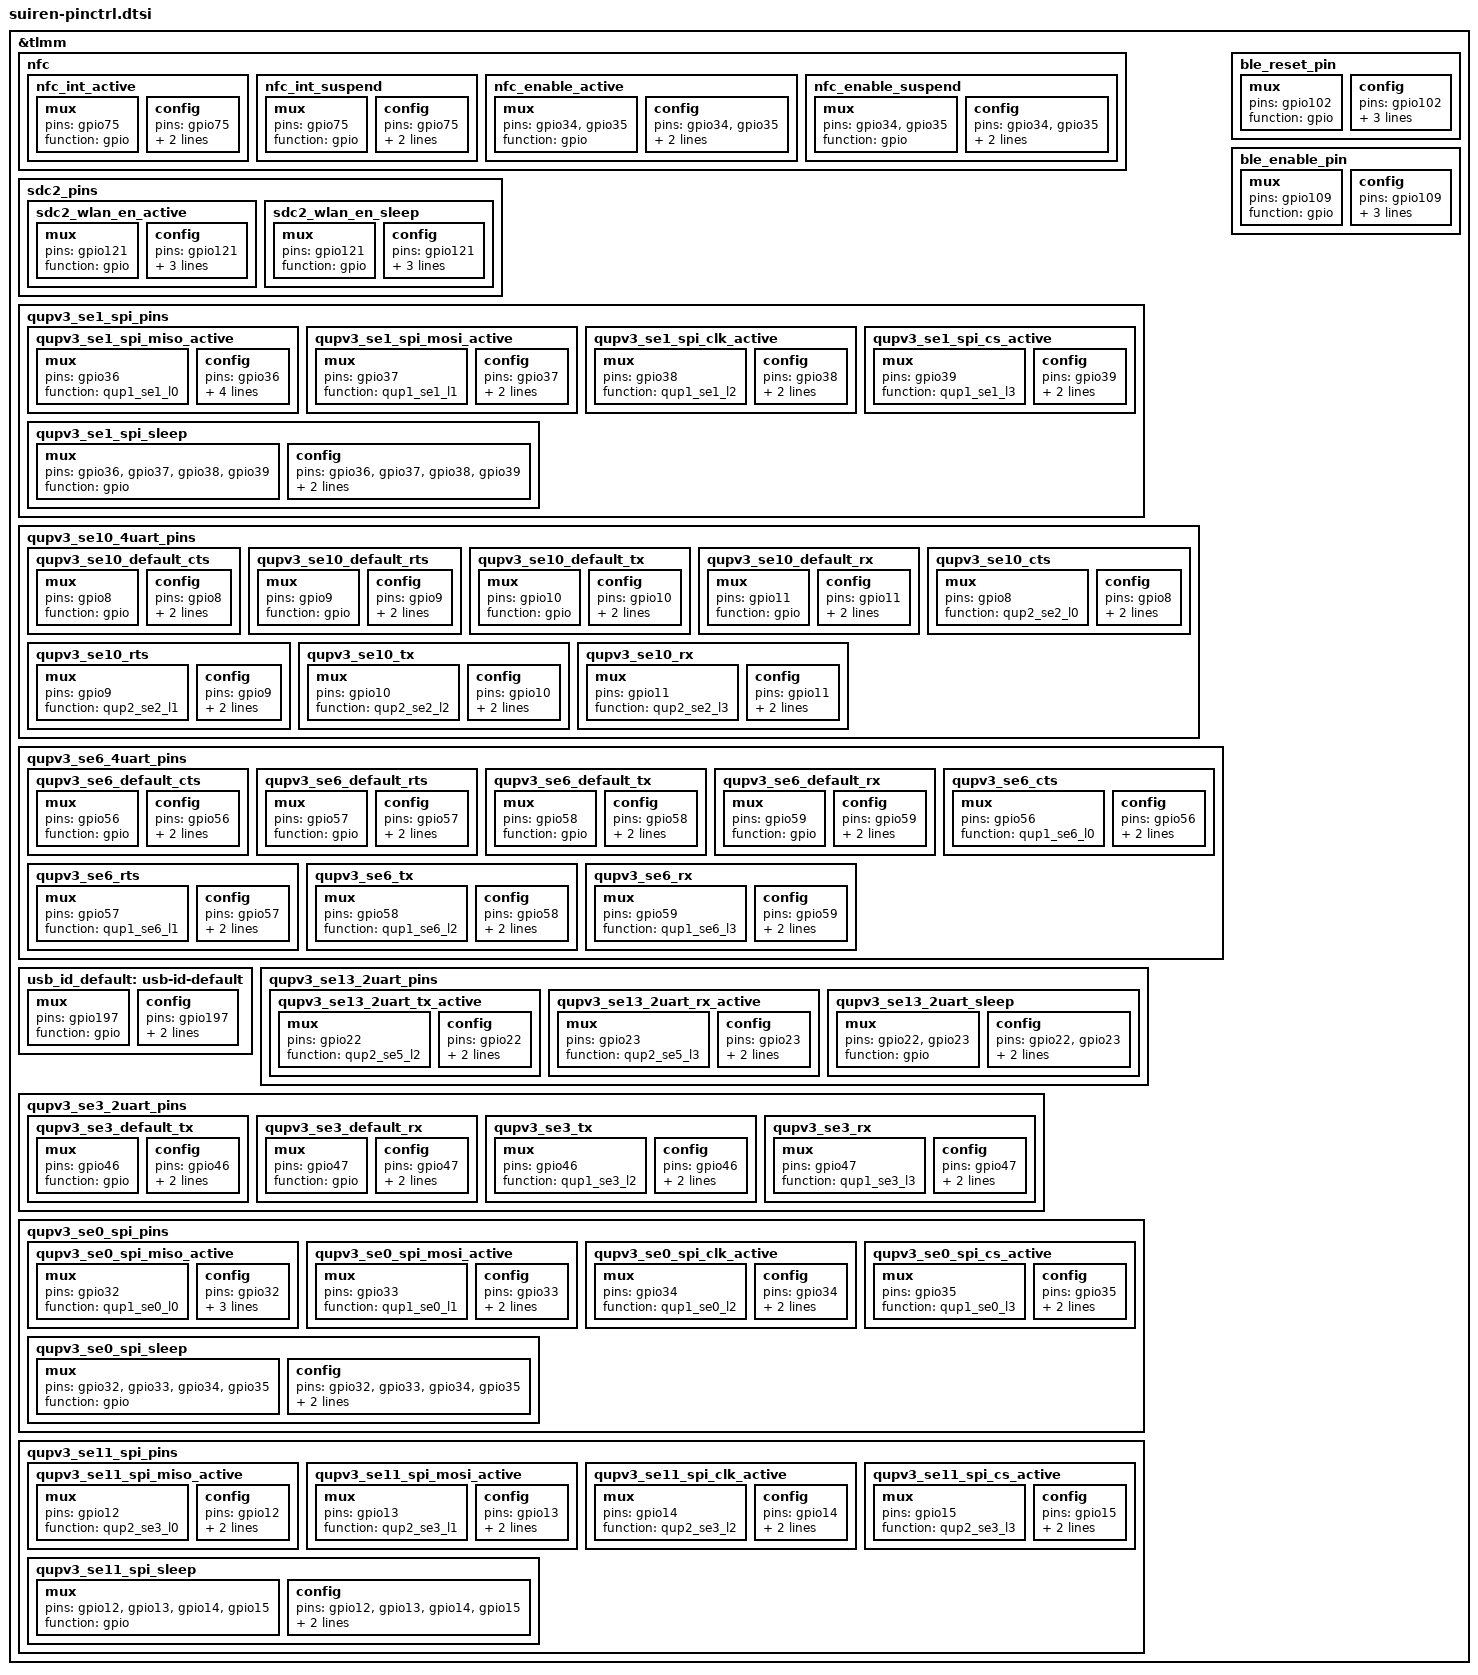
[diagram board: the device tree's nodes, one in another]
/*for suiren pinctrl */
&tlmm {
	nfc {
		nfc_int_active: nfc_int_active {
			/* active state */
			mux {
				/* NFC Read Interrupt */
				pins = "gpio75";
				function = "gpio";
			};

			config {
				pins = "gpio75";
				drive-strength = <2>; /* 2 MA */
				bias-pull-down;
			};
		};

		nfc_int_suspend: nfc_int_suspend {
			/* sleep state */
			mux {
				/* NFC Read Interrupt */
				pins = "gpio75";
				function = "gpio";
			};

			config {
				pins = "gpio75";
				drive-strength = <2>; /* 2 MA */
				bias-pull-down;
			};
		};

		nfc_enable_active: nfc_enable_active {
			mux {
				/* Enable, and Clock request gpios */
				pins = "gpio34", "gpio35";
				function = "gpio";
			};

			config {
				pins = "gpio34", "gpio35";
				drive-strength = <2>; /* 2 MA */
				bias-disable;
			};
		};

		nfc_enable_suspend: nfc_enable_suspend {
			mux {
				pins = "gpio34", "gpio35";
				function = "gpio";
			};

			config {
				pins = "gpio34", "gpio35";
				drive-strength = <2>; /* 2 MA */
				bias-disable;
			};
		};
	}; //nfc

	sdc2_pins {
		sdc2_wlan_en_active: sdc2_wlan_en_active {
			mux {
				pins = "gpio121";
				function = "gpio";
			};
			config {
				pins = "gpio121";
				drive-strength = <16>;
				output-high;
				bias-pull-up;
			};
		};
		sdc2_wlan_en_sleep: sdc2_wlan_en_sleep {
			mux {
				pins = "gpio121";
				function = "gpio";
			};
			config {
				pins = "gpio121";
				drive-strength = <2>;
				output-low;
				bias-pull-down;
			};
		};
	}; //wlan

	qupv3_se1_spi_pins: qupv3_se1_spi_pins {
		qupv3_se1_spi_miso_active: qupv3_se1_spi_miso_active {
			mux {
				pins = "gpio36";
				function = "qup1_se1_l0";
			};
			config {
				pins = "gpio36";
				drive-strength = <6>;
				bias-disable;
				bias-no-pull;
				input-enable;
			};
		};
		qupv3_se1_spi_mosi_active: qupv3_se1_spi_mosi_active {
			mux {
				pins = "gpio37";
				function = "qup1_se1_l1";
			};
			config {
				pins = "gpio37";
				drive-strength = <6>;
				bias-disable;
			};
		};
		qupv3_se1_spi_clk_active: qupv3_se1_spi_clk_active {
			mux {
				pins = "gpio38";
				function = "qup1_se1_l2";
			};
			config {
				pins = "gpio38";
				drive-strength = <6>;
				bias-disable;
			};
		};
		qupv3_se1_spi_cs_active: qupv3_se1_spi_cs_active {
			mux {
				pins = "gpio39";
				function = "qup1_se1_l3";
			};
			config {
				pins = "gpio39";
				drive-strength = <6>;
				bias-disable;
			};
		};
		qupv3_se1_spi_sleep: qupv3_se1_spi_sleep {
			mux {
				pins = "gpio36", "gpio37",
					"gpio38", "gpio39";
				function = "gpio";
			};
			config {
				pins = "gpio36", "gpio37",
					"gpio38", "gpio39";
				drive-strength = <6>;
				bias-disable;
			};
		};
	};

	/* bluetooth1 */
	qupv3_se10_4uart_pins: qupv3_se10_4uart_pins {
		qupv3_se10_default_cts: qupv3_se10_default_cts {
			mux {
				pins = "gpio8";
				function = "gpio";
			};
			config {
				pins = "gpio8";
				drive-strength = <2>;
				bias-disable;
			};
		};
		qupv3_se10_default_rts: qupv3_se10_default_rts {
			mux {
				pins = "gpio9";
				function = "gpio";
			};
			config {
				pins = "gpio9";
				drive-strength = <2>;
				bias-pull-down;
			};
		};
		qupv3_se10_default_tx: qupv3_se10_default_tx {
			mux {
				pins = "gpio10";
				function = "gpio";
			};
			config {
				pins = "gpio10";
				drive-strength = <2>;
				bias-pull-up;
			};
		};
		qupv3_se10_default_rx: qupv3_se10_default_rx {
			mux {
				pins = "gpio11";
				function = "gpio";
			};
			config {
				pins = "gpio11";
				drive-strength = <2>;
				bias-pull-down;
			};
		};
		qupv3_se10_cts: qupv3_se10_cts {
			mux {
				pins = "gpio8";
				function = "qup2_se2_l0";
			};
			config {
				pins = "gpio8";
				drive-strength = <2>;
				bias-disable;
			};
		};
		qupv3_se10_rts: qupv3_se10_rts {
			mux {
				pins = "gpio9";
				function = "qup2_se2_l1";
			};
			config {
				pins = "gpio9";
				drive-strength = <2>;
				bias-pull-down;
			};
		};
		qupv3_se10_tx: qupv3_se10_tx {
			mux {
				pins = "gpio10";
				function = "qup2_se2_l2";
			};
			config {
				pins = "gpio10";
				drive-strength = <2>;
				bias-pull-up;
			};
		};
		qupv3_se10_rx: qupv3_se10_rx {
			mux {
				pins = "gpio11";
				function = "qup2_se2_l3";
			};
			config {
				pins = "gpio11";
				drive-strength = <2>;
				bias-disable;
			};
		};
	}; // bluetooth1

	/* bluetooth le controller */
	qupv3_se6_4uart_pins: qupv3_se6_4uart_pins {
		qupv3_se6_default_cts: qupv3_se6_default_cts {
			mux {
				pins = "gpio56";
				function = "gpio";
			};
			config {
				pins = "gpio56";
				drive-strength = <2>;
				bias-disable;
			};
		};
		qupv3_se6_default_rts: qupv3_se6_default_rts {
			mux {
				pins = "gpio57";
				function = "gpio";
			};
			config {
				pins = "gpio57";
				drive-strength = <2>;
				bias-pull-down;
			};
		};
		qupv3_se6_default_tx: qupv3_se6_default_tx {
			mux {
				pins = "gpio58";
				function = "gpio";
			};
			config {
				pins = "gpio58";
				drive-strength = <2>;
				bias-pull-up;
			};
		};
		qupv3_se6_default_rx: qupv3_se6_default_rx {
			mux {
				pins = "gpio59";
				function = "gpio";
			};
			config {
				pins = "gpio59";
				drive-strength = <2>;
				bias-pull-down;
			};
		};
		qupv3_se6_cts: qupv3_se6_cts {
			mux {
				pins = "gpio56";
				function = "qup1_se6_l0";
			};
			config {
				pins = "gpio56";
				drive-strength = <2>;
				bias-disable;
			};
		};
		qupv3_se6_rts: qupv3_se6_rts {
			mux {
				pins = "gpio57";
				function = "qup1_se6_l1";
			};
			config {
				pins = "gpio57";
				drive-strength = <2>;
				bias-pull-down;
			};
		};
		qupv3_se6_tx: qupv3_se6_tx {
			mux {
				pins = "gpio58";
				function = "qup1_se6_l2";
			};
			config {
				pins = "gpio58";
				drive-strength = <2>;
				bias-pull-up;
			};
		};
		qupv3_se6_rx: qupv3_se6_rx {
			mux {
				pins = "gpio59";
				function = "qup1_se6_l3";
			};
			config {
				pins = "gpio59";
				drive-strength = <2>;
				bias-disable;
			};
		};
	};
	ble_reset_pin: ble_reset_pin {
		mux {
			pins = "gpio102";
			function = "gpio";
			};
		config {
			pins = "gpio102";
			drive-strength = <2>;
			output-low;
			bias-pull-down;
			};
	};
	ble_enable_pin: ble_enable_pin {
		mux {
			pins = "gpio109";
			function = "gpio";
			};
		config {
			pins = "gpio109";
			drive-strength = <2>;
			output-low;
			bias-pull-down;
			};
	};

	usb_id_default: usb-id-default {
		mux {
			pins = "gpio197";
			function = "gpio";
		};

		config {
			pins = "gpio197";
			drive-strength = <2>;
			bias-pull-up;
		};
	};

	qupv3_se13_2uart_pins: qupv3_se13_2uart_pins {
		qupv3_se13_2uart_tx_active: qupv3_se13_2uart_tx_active  {
			mux {
				pins = "gpio22";
				function = "qup2_se5_l2";
			};

			config {
				pins = "gpio22";
				drive-strength = <2>;
				bias-disable;
			};
		};

		qupv3_se13_2uart_rx_active: qupv3_se13_2uart_rx_active  {
			mux {
				pins = "gpio23";
				function = "qup2_se5_l3";
			};

			config {
				pins = "gpio23";
				drive-strength = <2>;
				bias-disable;
			};
		};
		qupv3_se13_2uart_sleep: qupv3_se13_2uart_sleep {
 			mux {
 				pins = "gpio22", "gpio23";
 				function = "gpio";
 			};
 
 			config {
				pins = "gpio22", "gpio23";
 				drive-strength = <2>;
				bias-pull-down;
 			};
 		};
	}; // MCU UART


	qupv3_se3_2uart_pins: qupv3_se3_2uart_pins {
		qupv3_se3_default_tx: qupv3_se3_default_tx {
			mux {
				pins = "gpio46";
				function = "gpio";
			};

			config {
				pins = "gpio46";
				drive-strength = <2>;
				bias-pull-up;
			};
		};

		qupv3_se3_default_rx: qupv3_se3_default_rx {
			mux {
				pins = "gpio47";
				function = "gpio";
			};

			config {
				pins = "gpio47";
				drive-strength = <2>;
				bias-pull-down;
			};
		};

		qupv3_se3_tx: qupv3_se3_tx {
			mux {
				pins = "gpio46";
				function = "qup1_se3_l2";
			};

			config {
				pins = "gpio46";
				drive-strength = <2>;
				bias-pull-up;
			};
		};

		qupv3_se3_rx: qupv3_se3_rx {
			mux {
				pins = "gpio47";
				function = "qup1_se3_l3";
			};

			config {
				pins = "gpio47";
				drive-strength = <2>;
				bias-disable;
			};
		};
	}; // Satellite UART

	qupv3_se0_spi_pins: qupv3_se0_spi_pins {
		qupv3_se0_spi_miso_active: qupv3_se0_spi_miso_active {
			mux {
				pins = "gpio32";
				function = "qup1_se0_l0";
			};

			config {
				pins = "gpio32";
				drive-strength = <6>;
				bias-no-pull;
                                input-enable;
			};
		};

		qupv3_se0_spi_mosi_active: qupv3_se0_spi_mosi_active {
			mux {
				pins = "gpio33";
				function = "qup1_se0_l1";
			};

			config {
				pins = "gpio33";
				drive-strength = <6>;
				bias-pull-down;
			};
		};

		qupv3_se0_spi_clk_active: qupv3_se0_spi_clk_active {
			mux {
				pins = "gpio34";
				function = "qup1_se0_l2";
			};

			config {
				pins = "gpio34";
				drive-strength = <6>;
				bias-pull-down;
			};
		};

		qupv3_se0_spi_cs_active: qupv3_se0_spi_cs_active {
			mux {
				pins = "gpio35";
				function = "qup1_se0_l3";
			};

			config {
				pins = "gpio35";
				drive-strength = <6>;
				bias-pull-down;
			};
		};

		qupv3_se0_spi_sleep: qupv3_se0_spi_sleep {
			mux {
				pins = "gpio32", "gpio33",
					"gpio34", "gpio35";
				function = "gpio";
			};

			config {
				pins = "gpio32", "gpio33",
					"gpio34", "gpio35";
				drive-strength = <6>;
				bias-pull-down;
			};
		};
	};

	qupv3_se11_spi_pins: qupv3_se11_spi_pins {
		qupv3_se11_spi_miso_active: qupv3_se11_spi_miso_active {
			mux {
				pins = "gpio12";
				function = "qup2_se3_l0";
			};

			config {
				pins = "gpio12";
				drive-strength = <6>;
				bias-disable;
			};
		};

		qupv3_se11_spi_mosi_active: qupv3_se11_spi_mosi_active {
			mux {
				pins = "gpio13";
				function = "qup2_se3_l1";
			};

			config {
				pins = "gpio13";
				drive-strength = <6>;
				bias-disable;
			};
		};

		qupv3_se11_spi_clk_active: qupv3_se11_spi_clk_active {
			mux {
				pins = "gpio14";
				function = "qup2_se3_l2";
			};

			config {
				pins = "gpio14";
				drive-strength = <6>;
				bias-disable;
			};
		};

		qupv3_se11_spi_cs_active: qupv3_se11_spi_cs_active {
			mux {
				pins = "gpio15";
				function = "qup2_se3_l3";
			};

			config {
				pins = "gpio15";
				drive-strength = <6>;
				bias-disable;
			};
		};

		qupv3_se11_spi_sleep: qupv3_se11_spi_sleep {
			mux {
				pins = "gpio12", "gpio13",
					"gpio14", "gpio15";
				function = "gpio";
			};

			config {
				pins = "gpio12", "gpio13",
					"gpio14", "gpio15";
				drive-strength = <6>;
				bias-disable;
			};
		};
	};
}; //tlmm
